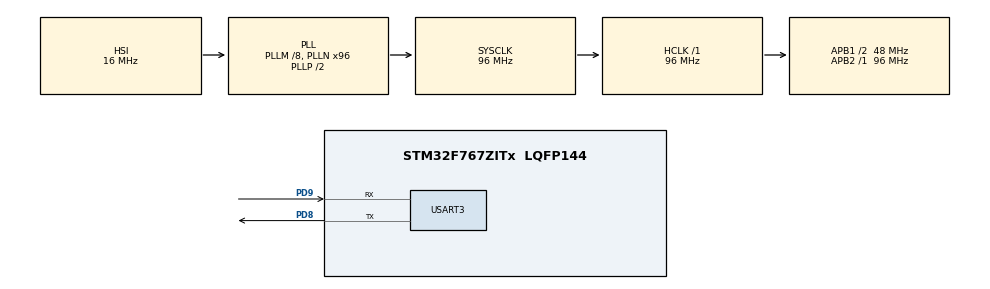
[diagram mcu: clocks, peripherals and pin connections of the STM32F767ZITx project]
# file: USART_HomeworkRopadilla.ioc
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Mcu.Family=STM32F7
Mcu.Name=STM32F767ZITx
Mcu.Package=LQFP144
NVIC.PriorityGroup=NVIC_PRIORITYGROUP_4
NVIC.USART3_IRQn=true\:0\:0\:false\:false\:true\:true\:true\:true
PD8.Mode=Asynchronous
PD8.Signal=USART3_TX
PD9.Mode=Asynchronous
PD9.Signal=USART3_RX
ProjectManager.HeapSize=0x200
ProjectManager.StackSize=0x400
ProjectManager.TargetToolchain=STM32CubeIDE
RCC.48MHZClocksFreq_Value=24000000
RCC.AHBFreq_Value=96000000
RCC.APB1CLKDivider=RCC_HCLK_DIV2
RCC.APB1Freq_Value=48000000
RCC.APB1TimFreq_Value=96000000
RCC.APB2Freq_Value=96000000
RCC.APB2TimFreq_Value=96000000
RCC.CortexFreq_Value=96000000
RCC.HCLKFreq_Value=96000000
RCC.HSE_VALUE=8000000
RCC.HSI_VALUE=16000000
RCC.LSE_VALUE=32768
RCC.PLLM=8
RCC.PLLMUL=RCC_PLL_MUL9
RCC.PLLN=96
RCC.PLLQ=4
RCC.PRESCALERUSB=RCC_USBCLKSOURCE_PLL_DIV1_5
RCC.SYSCLKFreq_VALUE=96000000
RCC.SYSCLKSource=RCC_SYSCLKSOURCE_PLLCLK
RCC.SYSCLKSourceVirtual=RCC_SYSCLKSOURCE_PLLCLK
RCC.USBFreq_Value=48000000
RCC.VCOOutputFreq_Value=192000000
USART3.VirtualMode-Asynchronous=VM_ASYNC
board=NUCLEO-F767ZI

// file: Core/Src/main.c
/* USER CODE BEGIN Header */
/**
  ******************************************************************************
  * @file           : main.c
  * @brief          : Main program body
  ******************************************************************************
  * @attention
  *
  * Copyright (c) 2025 STMicroelectronics.
  * All rights reserved.
  *
  * This software is licensed under terms that can be found in the LICENSE file
  * in the root directory of this software component.
  * If no LICENSE file comes with this software, it is provided AS-IS.
  *
  ******************************************************************************
  */
/* USER CODE END Header */
#include "main.h"

/* USER CODE BEGIN PD */
#define RX_BUFFER_SIZE 32
/* USER CODE END PD */

UART_HandleTypeDef huart3;

/* USER CODE BEGIN PV */
#define CMD_MAX_LENGTH 32

uint8_t uart_byte;
char command_buffer[CMD_MAX_LENGTH];
uint8_t command_index = 0;
volatile uint8_t command_ready = 0;
/* USER CODE END PV */

void SystemClock_Config(void);
static void MX_GPIO_Init(void);
static void MX_USART3_UART_Init(void);
/* USER CODE BEGIN PFP */
void ParseCommand(char *cmd);
/* USER CODE END PFP */

/* USER CODE BEGIN 0 */
void HAL_UART_RxCpltCallback(UART_HandleTypeDef *huart)
{
  if (huart->Instance == USART3) {
    if (uart_byte == '}') {
      if (command_index < CMD_MAX_LENGTH - 1) {
        command_buffer[command_index++] = uart_byte;
      }
      command_buffer[command_index] = '\0';  // Null-terminate
      command_ready = 1;
      command_index = 0;
    } else {
      if (command_index < CMD_MAX_LENGTH - 1) {
        command_buffer[command_index++] = uart_byte;
      } else {
        command_index = 0;  // Reset on overflow
      }
    }

    // Continue receiving next byte
    HAL_UART_Receive_IT(&huart3, &uart_byte, 1);
  }
}

void ParseCommand(char *cmd)
{
    HAL_UART_Transmit(&huart3, (uint8_t*)"Parsing...\r\n", 13, HAL_MAX_DELAY);

    // Find end of message
    char *end = strchr(cmd, '}');
    if (!end) {
        HAL_UART_Transmit(&huart3, (uint8_t*)"Missing closing }\r\n", 20, HAL_MAX_DELAY);
        return;
    }
    *(end + 1) = '\0';  // Terminate after the first }

    // Basic validation
    if (strncmp(cmd, "{LED:", 5) != 0 || strncmp(&cmd[8], "STATE:", 6) != 0) {
        HAL_UART_Transmit(&huart3, (uint8_t*)"Bad format\r\n", 13, HAL_MAX_DELAY);
        return;
    }

    // Extract ID
    char led_id[3] = { cmd[5], cmd[6], '\0' };

    // Extract ON/OFF
    char state[4] = {0};
    int state_len = end - &cmd[14];  // How many chars between STATE: and }

    strncpy(state, &cmd[14], state_len);
    state[state_len] = '\0';

    GPIO_PinState pin_state = (strcmp(state, "ON") == 0) ? GPIO_PIN_SET :
                              (strcmp(state, "OFF") == 0) ? GPIO_PIN_RESET : 255;

    if (pin_state == 255) {
        HAL_UART_Transmit(&huart3, (uint8_t*)"Unknown state\r\n", 16, HAL_MAX_DELAY);
        return;
    }

    if (strcmp(led_id, "01") == 0) {
        HAL_GPIO_WritePin(GPIOB, GPIO_PIN_0, pin_state);
        HAL_UART_Transmit(&huart3, (uint8_t*)"Green toggled\r\n", 16, HAL_MAX_DELAY);
    } else if (strcmp(led_id, "02") == 0) {
        HAL_GPIO_WritePin(GPIOB, GPIO_PIN_7, pin_state);
        HAL_UART_Transmit(&huart3, (uint8_t*)"Blue toggled\r\n", 15, HAL_MAX_DELAY);
    } else if (strcmp(led_id, "03") == 0) {
        HAL_GPIO_WritePin(GPIOB, GPIO_PIN_14, pin_state);
        HAL_UART_Transmit(&huart3, (uint8_t*)"Red toggled\r\n", 14, HAL_MAX_DELAY);
    } else {
        HAL_UART_Transmit(&huart3, (uint8_t*)"Unknown LED\r\n", 14, HAL_MAX_DELAY);
    }
}

/* USER CODE END 0 */

int main(void)
{

  /* MCU Configuration--------------------------------------------------------*/

  /* Reset of all peripherals, Initializes the Flash interface and the Systick. */
  HAL_Init();

  /* Configure the system clock */
  SystemClock_Config();

  /* Initialize all configured peripherals */
  MX_GPIO_Init();

  HAL_GPIO_TogglePin(GPIOB, GPIO_PIN_0);   // LD1
  HAL_Delay(1000);
  HAL_GPIO_TogglePin(GPIOB, GPIO_PIN_7);   // LD2
  HAL_Delay(1000);
  HAL_GPIO_TogglePin(GPIOB, GPIO_PIN_14);  // LD3
  HAL_Delay(1000);
  HAL_GPIO_TogglePin(GPIOB, GPIO_PIN_0);   // LD1
	HAL_Delay(1000);
	HAL_GPIO_TogglePin(GPIOB, GPIO_PIN_7);   // LD2
	HAL_Delay(1000);
	HAL_GPIO_TogglePin(GPIOB, GPIO_PIN_14);  // LD3
	HAL_Delay(1000);

  MX_USART3_UART_Init();
  /* USER CODE BEGIN 2 */
  char *startup_msg = "STM32 Ready. Send LED commands...\r\n";
  HAL_UART_Transmit(&huart3, (uint8_t*)startup_msg, strlen(startup_msg), HAL_MAX_DELAY);
  HAL_UART_Receive_IT(&huart3, &uart_byte, 1);
  /* USER CODE END 2 */

  /* Infinite loop */
  /* USER CODE BEGIN WHILE */
  while (1)
  {
	  if (command_ready) {
	    command_ready = 0;

	    HAL_UART_Transmit(&huart3, (uint8_t*)"CMD: ", 5, HAL_MAX_DELAY);
	    HAL_UART_Transmit(&huart3, (uint8_t*)command_buffer, RX_BUFFER_SIZE, HAL_MAX_DELAY);
	    HAL_UART_Transmit(&huart3, (uint8_t*)"\r\n", 2, HAL_MAX_DELAY);

	    ParseCommand(command_buffer);
	  }

    /* USER CODE END WHILE */

  }
}

void SystemClock_Config(void)
{
  RCC_OscInitTypeDef RCC_OscInitStruct = {0};
  RCC_ClkInitTypeDef RCC_ClkInitStruct = {0};

  /** Configure the main internal regulator output voltage
  */
  __HAL_RCC_PWR_CLK_ENABLE();
  __HAL_PWR_VOLTAGESCALING_CONFIG(PWR_REGULATOR_VOLTAGE_SCALE3);

  /** Initializes the RCC Oscillators according to the specified parameters
  * in the RCC_OscInitTypeDef structure.
  */
  RCC_OscInitStruct.OscillatorType = RCC_OSCILLATORTYPE_HSI;
  RCC_OscInitStruct.HSIState = RCC_HSI_ON;
  RCC_OscInitStruct.HSICalibrationValue = RCC_HSICALIBRATION_DEFAULT;
  RCC_OscInitStruct.PLL.PLLState = RCC_PLL_ON;
  RCC_OscInitStruct.PLL.PLLSource = RCC_PLLSOURCE_HSI;
  RCC_OscInitStruct.PLL.PLLM = 8;
  RCC_OscInitStruct.PLL.PLLN = 96;
  RCC_OscInitStruct.PLL.PLLP = RCC_PLLP_DIV2;
  RCC_OscInitStruct.PLL.PLLQ = 4;
  RCC_OscInitStruct.PLL.PLLR = 2;
  if (HAL_RCC_OscConfig(&RCC_OscInitStruct) != HAL_OK)
  {
    Error_Handler();
  }

  /** Activate the Over-Drive mode
  */
  if (HAL_PWREx_EnableOverDrive() != HAL_OK)
  {
    Error_Handler();
  }

  /** Initializes the CPU, AHB and APB buses clocks
  */
  RCC_ClkInitStruct.ClockType = RCC_CLOCKTYPE_HCLK|RCC_CLOCKTYPE_SYSCLK
                              |RCC_CLOCKTYPE_PCLK1|RCC_CLOCKTYPE_PCLK2;
  RCC_ClkInitStruct.SYSCLKSource = RCC_SYSCLKSOURCE_PLLCLK;
  RCC_ClkInitStruct.AHBCLKDivider = RCC_SYSCLK_DIV1;
  RCC_ClkInitStruct.APB1CLKDivider = RCC_HCLK_DIV2;
  RCC_ClkInitStruct.APB2CLKDivider = RCC_HCLK_DIV1;

  if (HAL_RCC_ClockConfig(&RCC_ClkInitStruct, FLASH_LATENCY_3) != HAL_OK)
  {
    Error_Handler();
  }
}

static void MX_USART3_UART_Init(void)
{

  huart3.Instance = USART3;
  huart3.Init.BaudRate = 115200;
  huart3.Init.WordLength = UART_WORDLENGTH_8B;
  huart3.Init.StopBits = UART_STOPBITS_1;
  huart3.Init.Parity = UART_PARITY_NONE;
  huart3.Init.Mode = UART_MODE_TX_RX;
  huart3.Init.HwFlowCtl = UART_HWCONTROL_NONE;
  huart3.Init.OverSampling = UART_OVERSAMPLING_16;
  huart3.Init.OneBitSampling = UART_ONE_BIT_SAMPLE_DISABLE;
  huart3.AdvancedInit.AdvFeatureInit = UART_ADVFEATURE_NO_INIT;
  if (HAL_UART_Init(&huart3) != HAL_OK)
  {
    Error_Handler();
  }

}

static void MX_GPIO_Init(void)
{
  /* USER CODE BEGIN MX_GPIO_Init_1 */
	GPIO_InitTypeDef GPIO_InitStruct = {0};
  /* USER CODE END MX_GPIO_Init_1 */

  /* GPIO Ports Clock Enable */
  __HAL_RCC_GPIOD_CLK_ENABLE();
  __HAL_RCC_GPIOB_CLK_ENABLE();

  /* USER CODE BEGIN MX_GPIO_Init_2 */
  GPIO_InitStruct.Pin = GPIO_PIN_0|GPIO_PIN_7|GPIO_PIN_14; // Change to your actual LED pins
    GPIO_InitStruct.Mode = GPIO_MODE_OUTPUT_PP;
    GPIO_InitStruct.Pull = GPIO_NOPULL;
    GPIO_InitStruct.Speed = GPIO_SPEED_FREQ_LOW;
    HAL_GPIO_Init(GPIOB, &GPIO_InitStruct);
  /* USER CODE END MX_GPIO_Init_2 */
}

void Error_Handler(void)
{
  __disable_irq();
  while (1)
  {
  }
}
